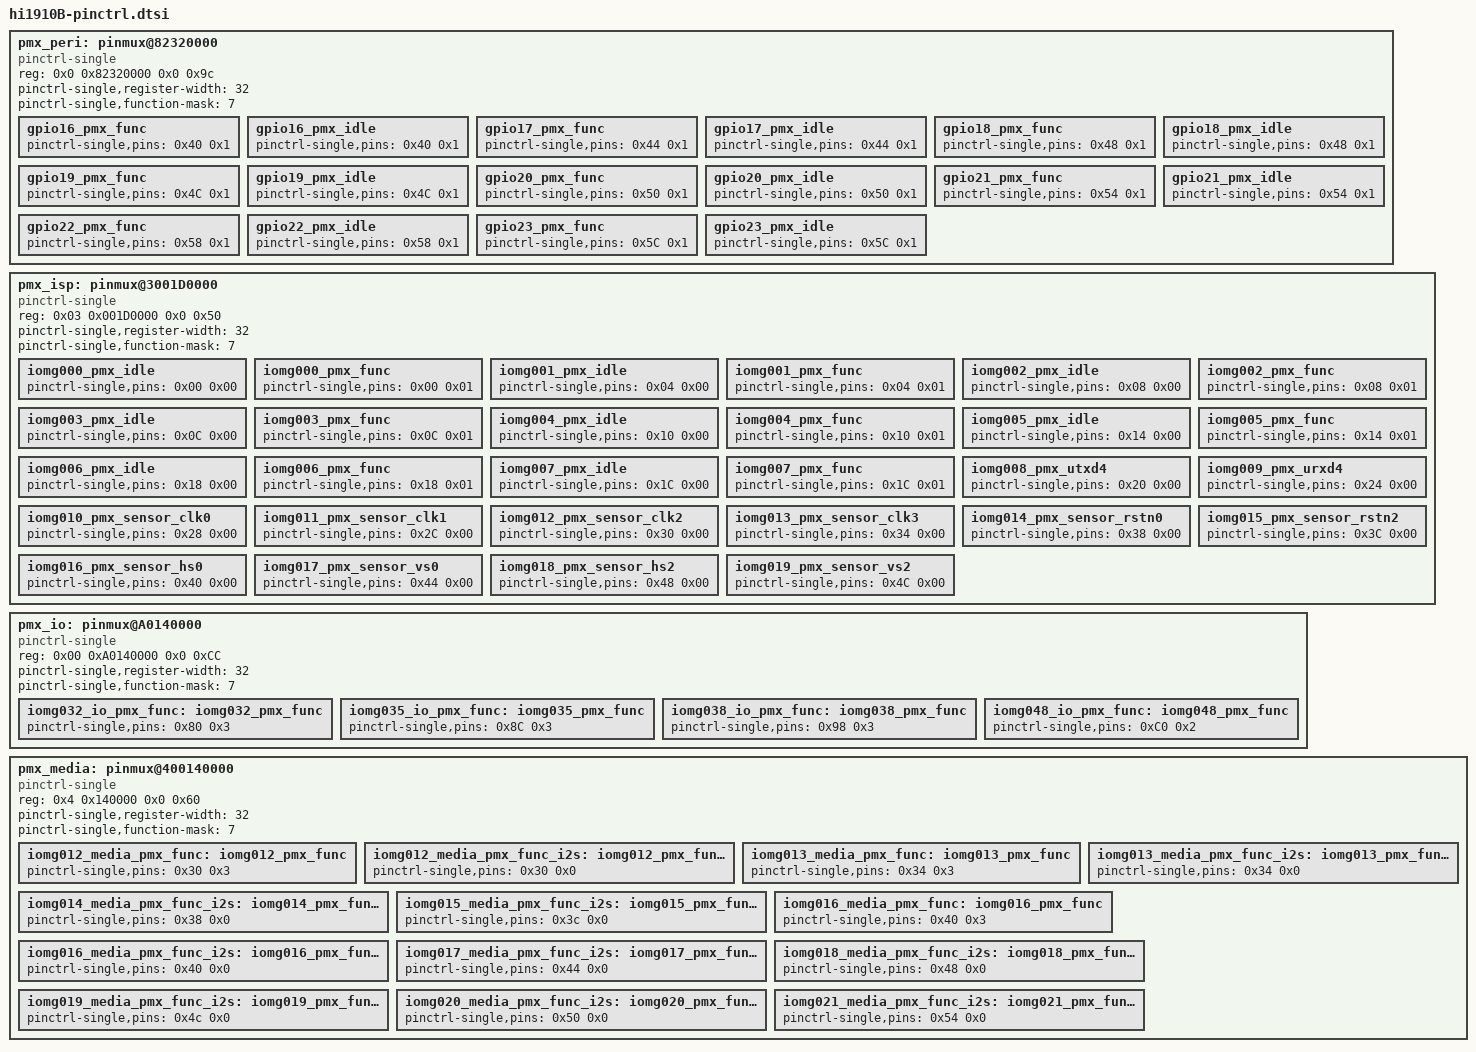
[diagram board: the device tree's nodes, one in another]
	pmx_peri: pinmux@82320000 {
		compatible = "pinctrl-single", "pinctrl-single1";
		reg = <0x0 0x82320000 0x0 0x9c>;
		#gpio-range-cells = <3>;
		pinctrl-single,register-width = <32>;
		pinctrl-single,function-mask = <7>;

		gpio16_pmx_func: gpio16_pmx_func {
			pinctrl-single,pins = <0x40    0x1>;
		};

		gpio16_pmx_idle: gpio16_pmx_idle {
			pinctrl-single,pins = <0x40    0x1>;
		};

		gpio17_pmx_func: gpio17_pmx_func {
			pinctrl-single,pins = <0x44    0x1>;
		};

		gpio17_pmx_idle: gpio17_pmx_idle {
			pinctrl-single,pins = <0x44    0x1>;
		};

		gpio18_pmx_func: gpio18_pmx_func {
			pinctrl-single,pins = <0x48    0x1>;
		};

		gpio18_pmx_idle: gpio18_pmx_idle {
			pinctrl-single,pins = <0x48    0x1>;
		};

		gpio19_pmx_func: gpio19_pmx_func {
			pinctrl-single,pins = <0x4C    0x1>;
		};

		gpio19_pmx_idle: gpio19_pmx_idle {
			pinctrl-single,pins = <0x4C    0x1>;
		};

		gpio20_pmx_func: gpio20_pmx_func {
			pinctrl-single,pins = <0x50    0x1>;
		};

		gpio20_pmx_idle: gpio20_pmx_idle {
			pinctrl-single,pins = <0x50    0x1>;
		};

		gpio21_pmx_func: gpio21_pmx_func {
			pinctrl-single,pins = <0x54    0x1>;
		};

		gpio21_pmx_idle: gpio21_pmx_idle {
			pinctrl-single,pins = <0x54    0x1>;
		};

		gpio22_pmx_func: gpio22_pmx_func {
			pinctrl-single,pins = <0x58    0x1>;
		};

		gpio22_pmx_idle: gpio22_pmx_idle {
			pinctrl-single,pins = <0x58    0x1>;
		};

		gpio23_pmx_func: gpio23_pmx_func {
			pinctrl-single,pins = <0x5C    0x1>;
		};

		gpio23_pmx_idle: gpio23_pmx_idle {
			pinctrl-single,pins = <0x5C    0x1>;
		};
	};

	pmx_isp: pinmux@3001D0000 {
		compatible = "pinctrl-single", "pinctrl-single1";
		reg = <0x03 0x001D0000 0x0 0x50>;
		#gpio-range-cells = <3>;
		pinctrl-single,register-width = <32>;
		pinctrl-single,function-mask = <7>;

		iomg000_pmx_idle: iomg000_pmx_idle {
			pinctrl-single,pins = <0x00    0x00>;
		};

		iomg000_pmx_func: iomg000_pmx_func {
			pinctrl-single,pins = <0x00    0x01>;
		};

		iomg001_pmx_idle: iomg001_pmx_idle {
			pinctrl-single,pins = <0x04    0x00>;
		};

		iomg001_pmx_func: iomg001_pmx_func {
			pinctrl-single,pins = <0x04    0x01>;
		};

		iomg002_pmx_idle: iomg002_pmx_idle {
			pinctrl-single,pins = <0x08    0x00>;
		};

		iomg002_pmx_func: iomg002_pmx_func {
			pinctrl-single,pins = <0x08    0x01>;
		};

		iomg003_pmx_idle: iomg003_pmx_idle {
			pinctrl-single,pins = <0x0C    0x00>;
		};

		iomg003_pmx_func: iomg003_pmx_func {
			pinctrl-single,pins = <0x0C    0x01>;
		};

		iomg004_pmx_idle: iomg004_pmx_idle {
			pinctrl-single,pins = <0x10    0x00>;
		};

		iomg004_pmx_func: iomg004_pmx_func {
			pinctrl-single,pins = <0x10    0x01>;
		};

		iomg005_pmx_idle: iomg005_pmx_idle {
			pinctrl-single,pins = <0x14    0x00>;
		};

		iomg005_pmx_func: iomg005_pmx_func {
			pinctrl-single,pins = <0x14    0x01>;
		};

		iomg006_pmx_idle: iomg006_pmx_idle {
			pinctrl-single,pins = <0x18    0x00>;
		};

		iomg006_pmx_func: iomg006_pmx_func {
			pinctrl-single,pins = <0x18    0x01>;
		};

		iomg007_pmx_idle: iomg007_pmx_idle {
			pinctrl-single,pins = <0x1C    0x00>;
		};

		iomg007_pmx_func: iomg007_pmx_func {
			pinctrl-single,pins = <0x1C    0x01>;
		};

		iomg008_pmx_utxd4: iomg008_pmx_utxd4 {
			pinctrl-single,pins = <0x20    0x00>;
		};

		iomg009_pmx_urxd4: iomg009_pmx_urxd4 {
			pinctrl-single,pins = <0x24    0x00>;
		};

		iomg010_pmx_sensor_clk0: iomg010_pmx_sensor_clk0 {
			pinctrl-single,pins = <0x28    0x00>;
		};

		iomg011_pmx_sensor_clk1: iomg011_pmx_sensor_clk1 {
			pinctrl-single,pins = <0x2C    0x00>;
		};

		iomg012_pmx_sensor_clk2: iomg012_pmx_sensor_clk2 {
			pinctrl-single,pins = <0x30    0x00>;
		};

		iomg013_pmx_sensor_clk3: iomg013_pmx_sensor_clk3 {
			pinctrl-single,pins = <0x34    0x00>;
		};

		iomg014_pmx_sensor_rstn0: iomg014_pmx_sensor_rstn0 {
			pinctrl-single,pins = <0x38    0x00>;
		};

		iomg015_pmx_sensor_rstn2: iomg015_pmx_sensor_rstn2 {
			pinctrl-single,pins = <0x3C    0x00>;
		};

		iomg016_pmx_sensor_hs0: iomg016_pmx_sensor_hs0 {
			pinctrl-single,pins = <0x40    0x00>;
		};

		iomg017_pmx_sensor_vs0: iomg017_pmx_sensor_vs0 {
			pinctrl-single,pins = <0x44    0x00>;
		};

		iomg018_pmx_sensor_hs2: iomg018_pmx_sensor_hs2 {
			pinctrl-single,pins = <0x48    0x00>;
		};

		iomg019_pmx_sensor_vs2: iomg019_pmx_sensor_vs2 {
			pinctrl-single,pins = <0x4C    0x00>;
		};
	};

	pmx_io: pinmux@A0140000 {
		compatible = "pinctrl-single", "pinctrl-single1";
		reg = <0x00 0xA0140000 0x0 0xCC>;
		#gpio-range-cells = <3>;
		pinctrl-single,register-width = <32>;
		pinctrl-single,function-mask = <7>;

		iomg032_io_pmx_func: iomg032_pmx_func {
			pinctrl-single,pins = <0x80    0x3>;
		};

		iomg035_io_pmx_func: iomg035_pmx_func {
			pinctrl-single,pins = <0x8C    0x3>;
		};

		iomg038_io_pmx_func: iomg038_pmx_func {
			pinctrl-single,pins = <0x98    0x3>;
		};

		iomg048_io_pmx_func: iomg048_pmx_func {
			pinctrl-single,pins = <0xC0    0x2>;
		};
	};

	pmx_media: pinmux@400140000 {
		compatible = "pinctrl-single", "pinctrl-single1";
		reg = <0x4 0x140000 0x0 0x60>;
		#gpio-range-cells = <3>;
		pinctrl-single,register-width = <32>;
		pinctrl-single,function-mask = <7>;

		iomg012_media_pmx_func: iomg012_pmx_func {
			pinctrl-single,pins = <0x30    0x3>;
		};
		iomg012_media_pmx_func_i2s: iomg012_pmx_func_i2s {
			pinctrl-single,pins = <0x30    0x0>;
		};

		iomg013_media_pmx_func: iomg013_pmx_func {
			pinctrl-single,pins = <0x34    0x3>;
		};
		iomg013_media_pmx_func_i2s: iomg013_pmx_func_i2s {
			pinctrl-single,pins = <0x34    0x0>;
		};
		iomg014_media_pmx_func_i2s: iomg014_pmx_func_i2s {
			pinctrl-single,pins = <0x38    0x0>;
		};
		iomg015_media_pmx_func_i2s: iomg015_pmx_func_i2s {
			pinctrl-single,pins = <0x3c    0x0>;
		};
		iomg016_media_pmx_func: iomg016_pmx_func {
			pinctrl-single,pins = <0x40    0x3>;
		};
		iomg016_media_pmx_func_i2s: iomg016_pmx_func_i2s {
			pinctrl-single,pins = <0x40    0x0>;
		};
		iomg017_media_pmx_func_i2s: iomg017_pmx_func_i2s {
			pinctrl-single,pins = <0x44    0x0>;
		};
		iomg018_media_pmx_func_i2s: iomg018_pmx_func_i2s {
			pinctrl-single,pins = <0x48    0x0>;
		};
		iomg019_media_pmx_func_i2s: iomg019_pmx_func_i2s {
			pinctrl-single,pins = <0x4c    0x0>;
		};
		iomg020_media_pmx_func_i2s: iomg020_pmx_func_i2s {
			pinctrl-single,pins = <0x50    0x0>;
		};
		iomg021_media_pmx_func_i2s: iomg021_pmx_func_i2s {
			pinctrl-single,pins = <0x54    0x0>;
		};
	};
